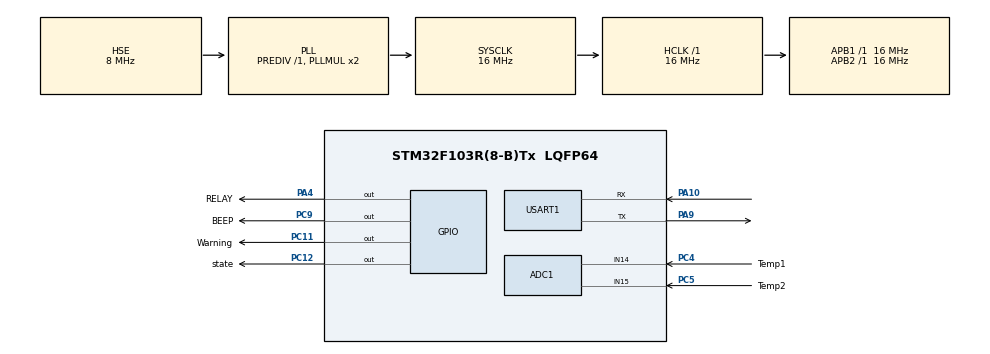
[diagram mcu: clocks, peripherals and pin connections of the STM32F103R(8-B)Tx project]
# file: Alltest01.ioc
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ADC1.Channel-0\#ChannelRegularConversion=ADC_CHANNEL_14
ADC1.NbrOfConversionFlag=1
ADC1.Rank-0\#ChannelRegularConversion=1
ADC1.SamplingTime-0\#ChannelRegularConversion=ADC_SAMPLETIME_1CYCLE_5
ADC1.master=1
Mcu.Family=STM32F1
Mcu.Name=STM32F103R(8-B)Tx
Mcu.Package=LQFP64
NVIC.ADC1_2_IRQn=true\:0\:0\:false\:false\:true\:true\:true
NVIC.PriorityGroup=NVIC_PRIORITYGROUP_4
NVIC.USART1_IRQn=true\:0\:0\:false\:false\:true\:true\:true
PA10.Mode=Asynchronous
PA10.Signal=USART1_RX
PA13.Mode=JTAG_4_pins
PA13.Signal=SYS_JTMS-SWDIO
PA14.Mode=JTAG_4_pins
PA14.Signal=SYS_JTCK-SWCLK
PA15.Mode=JTAG_4_pins
PA15.Signal=SYS_JTDI
PA4.GPIO_Label=RELAY
PA4.Signal=GPIO_Output
PA9.Mode=Asynchronous
PA9.Signal=USART1_TX
PB3.Mode=JTAG_4_pins
PB3.Signal=SYS_JTDO-TRACESWO
PC11.GPIO_Label=Warning
PC11.PinState=GPIO_PIN_SET
PC11.Signal=GPIO_Output
PC12.GPIO_Label=state
PC12.PinState=GPIO_PIN_SET
PC12.Signal=GPIO_Output
PC4.GPIO_Label=Temp1
PC4.Signal=ADCx_IN14
PC5.GPIO_Label=Temp2
PC5.Signal=ADCx_IN15
PC9.GPIO_Label=BEEP
PC9.Signal=GPIO_Output
PD0-OSC_IN.Mode=HSE-External-Oscillator
PD0-OSC_IN.Signal=RCC_OSC_IN
PD1-OSC_OUT.Mode=HSE-External-Oscillator
PD1-OSC_OUT.Signal=RCC_OSC_OUT
ProjectManager.HeapSize=0x200
ProjectManager.StackSize=0x400
ProjectManager.TargetToolchain=MDK-ARM V5.27
RCC.AHBFreq_Value=16000000
RCC.APB1Freq_Value=16000000
RCC.APB1TimFreq_Value=16000000
RCC.APB2Freq_Value=16000000
RCC.APB2TimFreq_Value=16000000
RCC.HCLKFreq_Value=16000000
RCC.PLLSourceVirtual=RCC_PLLSOURCE_HSE
RCC.SYSCLKFreq_VALUE=16000000
RCC.SYSCLKSource=RCC_SYSCLKSOURCE_PLLCLK
RCC.USBFreq_Value=16000000
SH.ADCx_IN14.0=ADC1_IN14,IN14
SH.ADCx_IN15.0=ADC1_IN15,IN15
USART1.VirtualMode=VM_ASYNC
board=custom

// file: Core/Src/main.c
/* USER CODE BEGIN Header */
/**
  ******************************************************************************
  * @file           : main.c
  * @brief          : Main program body
  ******************************************************************************
  * @attention
  *
  * <h2><center>&copy; Copyright (c) 2021 STMicroelectronics.
  * All rights reserved.</center></h2>
  *
  * This software component is licensed by ST u
	nder BSD 3-Clause license,
  * the "License"; You may not use this file except in compliance with the
  * License. You may obtain a copy of the License at:
  *                        opensource.org/licenses/BSD-3-Clause
  *
  ******************************************************************************
  */
/* USER CODE END Header */
#include "main.h"
#include "adc.h"
#include "usart.h"
#include "gpio.h"

void SystemClock_Config(void);

int main(void)
{

  /* MCU Configuration--------------------------------------------------------*/

  /* Reset of all peripherals, Initializes the Flash interface and the Systick. */
  HAL_Init();

  /* Configure the system clock */
  SystemClock_Config();

  /* Initialize all configured peripherals */
  MX_GPIO_Init();
  MX_ADC1_Init();
  MX_USART1_UART_Init();

  /* Infinite loop */
  /* USER CODE BEGIN WHILE */
  while (1)
  {
		HAL_Delay(1000);
		HAL_GPIO_TogglePin(BEEP_GPIO_Port,BEEP_Pin);
		HAL_Delay(1000);
		HAL_GPIO_TogglePin(Warning_GPIO_Port,Warning_Pin);
		HAL_Delay(1000);
		HAL_GPIO_TogglePin(state_GPIO_Port,state_Pin);
		HAL_Delay(1000);
		HAL_GPIO_TogglePin(RELAY_GPIO_Port,RELAY_Pin);
    /* USER CODE END WHILE */

  }
}

void SystemClock_Config(void)
{
  RCC_OscInitTypeDef RCC_OscInitStruct = {0};
  RCC_ClkInitTypeDef RCC_ClkInitStruct = {0};
  RCC_PeriphCLKInitTypeDef PeriphClkInit = {0};

  /** Initializes the RCC Oscillators according to the specified parameters
  * in the RCC_OscInitTypeDef structure.
  */
  RCC_OscInitStruct.OscillatorType = RCC_OSCILLATORTYPE_HSE;
  RCC_OscInitStruct.HSEState = RCC_HSE_ON;
  RCC_OscInitStruct.HSEPredivValue = RCC_HSE_PREDIV_DIV1;
  RCC_OscInitStruct.HSIState = RCC_HSI_ON;
  RCC_OscInitStruct.PLL.PLLState = RCC_PLL_ON;
  RCC_OscInitStruct.PLL.PLLSource = RCC_PLLSOURCE_HSE;
  RCC_OscInitStruct.PLL.PLLMUL = RCC_PLL_MUL2;
  if (HAL_RCC_OscConfig(&RCC_OscInitStruct) != HAL_OK)
  {
    Error_Handler();
  }
  /** Initializes the CPU, AHB and APB buses clocks
  */
  RCC_ClkInitStruct.ClockType = RCC_CLOCKTYPE_HCLK|RCC_CLOCKTYPE_SYSCLK
                              |RCC_CLOCKTYPE_PCLK1|RCC_CLOCKTYPE_PCLK2;
  RCC_ClkInitStruct.SYSCLKSource = RCC_SYSCLKSOURCE_PLLCLK;
  RCC_ClkInitStruct.AHBCLKDivider = RCC_SYSCLK_DIV1;
  RCC_ClkInitStruct.APB1CLKDivider = RCC_HCLK_DIV1;
  RCC_ClkInitStruct.APB2CLKDivider = RCC_HCLK_DIV1;

  if (HAL_RCC_ClockConfig(&RCC_ClkInitStruct, FLASH_LATENCY_0) != HAL_OK)
  {
    Error_Handler();
  }
  PeriphClkInit.PeriphClockSelection = RCC_PERIPHCLK_ADC;
  PeriphClkInit.AdcClockSelection = RCC_ADCPCLK2_DIV2;
  if (HAL_RCCEx_PeriphCLKConfig(&PeriphClkInit) != HAL_OK)
  {
    Error_Handler();
  }
}

void Error_Handler(void)
{
  __disable_irq();
  while (1)
  {
  }
}

/************************ (C) COPYRIGHT STMicroelectronics *****END OF FILE****/
